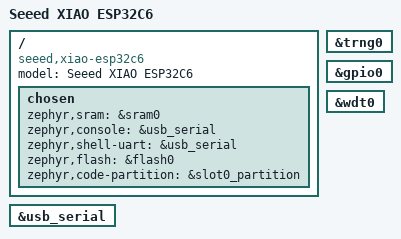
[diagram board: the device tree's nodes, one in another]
/*
 * Copyright (c) 2024 Mario Paja
 *
 * SPDX-License-Identifier: Apache-2.0
 */

/dts-v1/;

#include <espressif/esp32c6/esp32c6_wroom_n4.dtsi>
#include "xiao_esp32c6-pinctrl.dtsi"
#include <zephyr/dt-bindings/input/input-event-codes.h>
#include <espressif/partitions_0x0_default.dtsi>

/ {
	model = "Seeed XIAO ESP32C6";
	compatible = "seeed,xiao-esp32c6";

	chosen {
		zephyr,sram = &sram0;
		zephyr,console = &usb_serial;
		zephyr,shell-uart = &usb_serial;
		zephyr,flash = &flash0;
		zephyr,code-partition = &slot0_partition;
	};

};

&trng0 {
	status = "okay";
};

&gpio0 {
	status = "okay";
};

&wdt0 {
	status = "okay";
};

&usb_serial {
	status = "okay";
};
